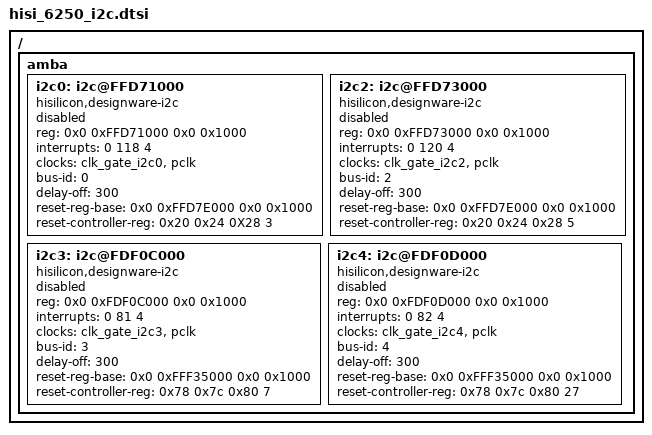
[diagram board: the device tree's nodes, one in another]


/{
	amba{
		i2c0: i2c@FFD71000 {
			compatible = "hisilicon,designware-i2c";
			reg = <0x0 0xFFD71000 0x0 0x1000>;
			interrupts = <0 118 4>;
			clocks = <&clk_gate_i2c0 &pclk>;
			clock-names = "clk_i2c", "apb_pclk";
			//dmas = <&iomcu_dma 2 &iomcu_dma 3>; /* rx channel ; tx channel */
			//dma-names = "rx", "tx";
			bus-id = <0>;
			delay-off = <300>;
			reset-reg-base = <0x0 0xFFD7E000 0x0 0x1000>; /* IOMCU_CONFIG */
			reset-controller-reg = <0x20 0x24 0X28 3>;
			status = "disabled";
		};

		i2c2: i2c@FFD73000 {
			compatible = "hisilicon,designware-i2c";
			reg = <0x0 0xFFD73000 0x0 0x1000>;
			interrupts = <0 120 4>;
			clocks = <&clk_gate_i2c2 &pclk>;
			clock-names = "clk_i2c", "apb_pclk";
			//dmas = <&iomcu_dma 6 &iomcu_dma 7>; /* rx channel ; tx channel, reserved */
			//dma-names = "rx", "tx";
			bus-id = <2>;
			delay-off = <300>;
			reset-reg-base = <0x0 0xFFD7E000 0x0 0x1000>; /* IOMCU_CONFIG */
			reset-controller-reg = <0x20 0x24 0x28 5>;
			status = "disabled";
		};

		i2c3: i2c@FDF0C000 {
			compatible = "hisilicon,designware-i2c";
			reg = <0x0 0xFDF0C000 0x0 0x1000>;
			interrupts = <0 81 4>;
			clocks = <&clk_gate_i2c3 &pclk>;
			clock-names = "clk_i2c", "apb_pclk";
			//dmas = <&dma0 12 &dma0 13>; /* rx channel ; tx channel */
			//dma-names = "rx", "tx";
			bus-id = <3>;
			delay-off = <300>;
			reset-reg-base = <0x0 0xFFF35000 0x0 0x1000>; /* PERI_CRG */
			reset-controller-reg = <0x78 0x7c 0x80 7>;
			status = "disabled";
		};

		i2c4: i2c@FDF0D000 {
			compatible = "hisilicon,designware-i2c";
			reg = <0x0 0xFDF0D000 0x0 0x1000>;
			interrupts = <0 82 4>;
			clocks = <&clk_gate_i2c4 &pclk>;
			clock-names = "clk_i2c", "apb_pclk";
			//dmas = <&dma0 14 &dma0 15>; /* rx channel ; tx channel */
			//dma-names = "rx", "tx";
			bus-id = <4>;
			delay-off = <300>;
			reset-reg-base = <0x0 0xFFF35000 0x0 0x1000>; /* PERI_CRG */
			reset-controller-reg = <0x78 0x7c 0x80 27>;
			status = "disabled";
		};
	};
};
